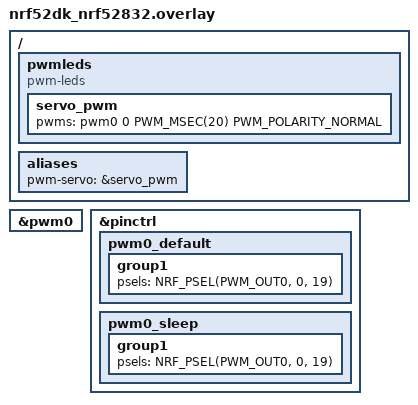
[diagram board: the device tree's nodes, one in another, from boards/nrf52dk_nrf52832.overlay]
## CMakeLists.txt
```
cmake_minimum_required(VERSION 3.20.0)
find_package(Zephyr REQUIRED HINTS $ENV{ZEPHYR_BASE})
project(base_node)

# Local source files
file(GLOB local_sources
    ${CMAKE_CURRENT_SOURCE_DIR}/src/*.c
    ${CMAKE_CURRENT_SOURCE_DIR}/lib/*.c
)
# Global source files
file(GLOB global_sources
    ${CMAKE_CURRENT_SOURCE_DIR}/../lib/rxBluetooth.c
    ${CMAKE_CURRENT_SOURCE_DIR}/../lib/txBluetooth.c
)

# Combine all sources
target_sources(app PRIVATE ${local_sources} ${global_sources})

# Include both local and global headers
target_include_directories(app PRIVATE
    ${CMAKE_CURRENT_SOURCE_DIR}/include
    ${CMAKE_CURRENT_SOURCE_DIR}/../include
)
```

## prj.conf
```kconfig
CONFIG_GPIO=y
CONFIG_PRINTK=y
CONFIG_PWM=y


# Bluetooth
CONFIG_BT=y
CONFIG_BT_DEVICE_NAME="base_node"
CONFIG_BT_CENTRAL=y
CONFIG_BT_PERIPHERAL=y
CONFIG_BT_OBSERVER=y
CONFIG_BT_SMP=y
CONFIG_BT_BONDABLE=y
CONFIG_BT_PRIVACY=y
CONFIG_BT_DEVICE_NAME_DYNAMIC=n
CONFIG_BT_DEVICE_APPEARANCE=0
CONFIG_BT_GATT_CLIENT=y
CONFIG_BT_MAX_CONN=2


CONFIG_ASSERT=y
CONFIG_GPIO=y
CONFIG_LOG=y
CONFIG_SERIAL=y
CONFIG_CONSOLE=y
CONFIG_UART_CONSOLE=y
CONFIG_UART_LINE_CTRL=y
CONFIG_SHELL=y
CONFIG_LOG_RUNTIME_FILTERING=y
```

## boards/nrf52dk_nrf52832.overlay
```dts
/ {
    pwmleds {
        compatible = "pwm-leds";

        servo_pwm: servo_pwm {
            pwms = <&pwm0 0 PWM_MSEC(20) PWM_POLARITY_NORMAL>;
        };
    };

    aliases {
        pwm-servo = &servo_pwm;
    };
};

/* Enable hardware PWM */
&pwm0 {
    status = "okay";
};
&pinctrl {
    pwm0_default: pwm0_default {
        group1 {
            psels = <NRF_PSEL(PWM_OUT0, 0, 19)>; // pin P0.19
        };
    };
    pwm0_sleep: pwm0_sleep {
        group1 {
            psels = <NRF_PSEL(PWM_OUT0, 0, 19)>;
        };
    };
};
```

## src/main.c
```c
#include <zephyr/kernel.h>
#include <zephyr/device.h>
#include "baseBluetooth.h"
#include "servo.h"
#include "CLIshell.h"
/* scheduling parameters */
#define STACKSIZE 				4096
#define PRIORITY 				7
#define PRIORITY_SENSOR			3

void main_task(void) {
    register_shell_commands();
}

K_THREAD_DEFINE(main_task_id, STACKSIZE, main_task, NULL, NULL, NULL, PRIORITY, 0, 0);
K_THREAD_DEFINE(bluetooth_receiver0_id, STACKSIZE, bluetooth_receiver0, NULL, NULL, NULL, PRIORITY, 0, 0);
```

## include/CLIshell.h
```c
#ifndef COMMANDS_H
#define COMMANDS_H

void register_shell_commands(void);

#endif //COMMANDS_H
```

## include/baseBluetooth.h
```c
#ifndef BASEBLUETOOTH_H
#define BASEBLUETOOTH_H

void bluetooth_receiver0(void);

#endif // BASEBLUETOOTH_H
```

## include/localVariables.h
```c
#ifndef LOCAL_VARIABLES_H
#define LOCAL_VARIABLES_H

#include <zephyr/kernel.h>
#include <stdbool.h>

extern volatile int latest_distance_cm;
extern volatile int latest_avg_value;
extern volatile bool door_locked;

#endif // LOCAL_VARIABLES_H
```

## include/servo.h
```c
#ifndef SERVO_H
#define SERVO_H
int set_servo_locked(bool locked);
#endif // SERVO_H
```
